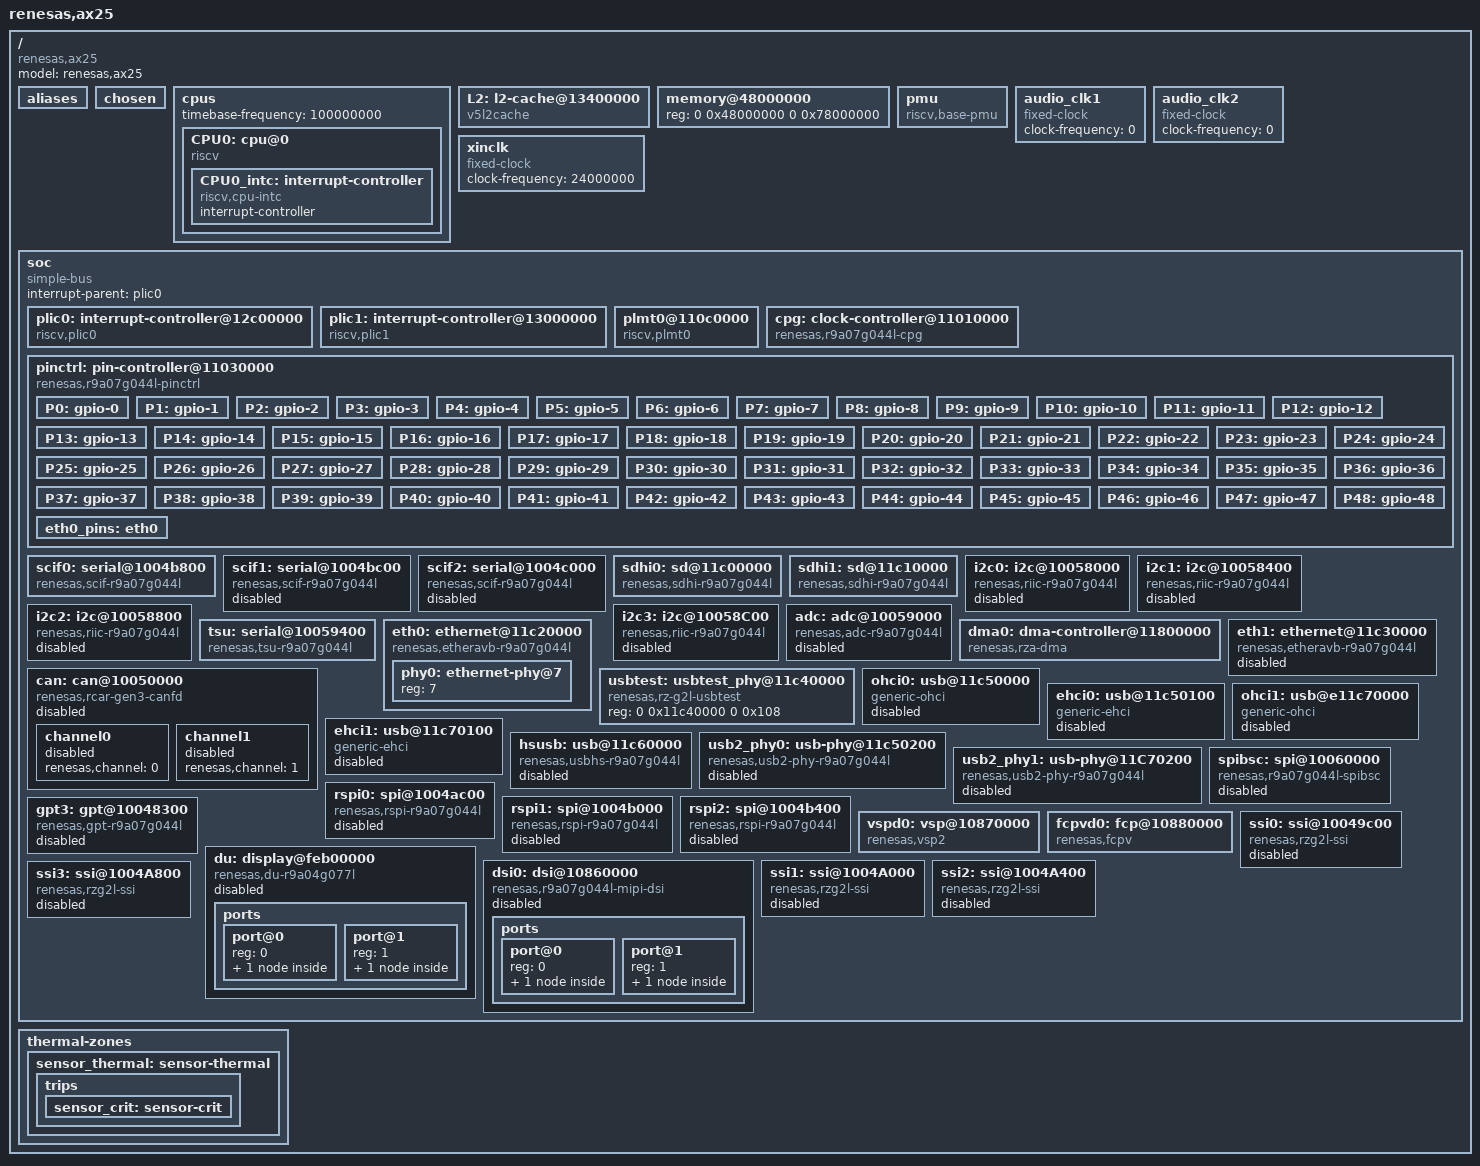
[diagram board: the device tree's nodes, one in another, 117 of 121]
// SPDX-License-Identifier: GPL-2.0
/*
 * Device Tree Source for the GR-Peach board
 *
 * Copyright (C) 2017 Jacopo Mondi <jacopo+renesas@jmondi.org>
 * Copyright (C) 2016 Renesas Electronics
 */

/dts-v1/;
#include <dt-bindings/gpio/gpio.h>
#include <dt-bindings/interrupt-controller/arm-gic.h>
#include <dt-bindings/clock/r9a07g044l-cpg.h>
#include <dt-bindings/pinctrl/rzg2l-pinctrl.h>

/ {
		#address-cells = <2>;
		#size-cells = <2>;
		compatible = "renesas,ax25";
		model = "renesas,ax25";

		aliases {
				serial0 = &scif0;
				i2c0 = &i2c0;
				i2c1 = &i2c1;
				i2c2 = &i2c2;
				i2c3 = &i2c3;
				spi0 = &rspi0;
				spi1 = &rspi1;
				spi2 = &rspi2;
		};

		chosen {
				bootargs = "console=ttyS0,115200n8	debug loglevel=7";
				stdout-path = "serial0:115200n8";
		};

		cpus {
				u-boot,dm-spl;
				#address-cells = <1>;
				#size-cells = <0>;
				timebase-frequency = <100000000>;
				CPU0: cpu@0 {
						u-boot,dm-spl;
						device_type = "cpu";
						reg = <0>;
						status = "okay";
						compatible = "riscv";
						riscv,isa = "rv64imafdc";
						riscv,priv-major = <1>;
						riscv,priv-minor = <10>;
						mmu-type = "riscv,sv39";
						clock-frequency = <100000000>;
						i-cache-size = <0x8000>;
						i-cache-line-size = <32>;
						d-cache-size = <0x8000>;
						d-cache-line-size = <32>;
						next-level-cache = <&L2>;
						CPU0_intc: interrupt-controller {
								u-boot,dm-spl;
								#interrupt-cells = <1>;
								interrupt-controller;
								compatible = "riscv,cpu-intc";
						};
				};
		};

		L2: l2-cache@13400000 {
				u-boot,dm-spl;
				compatible = "v5l2cache";
				cache-level = <2>;
				cache-size = <0x40000>;
				reg = <0x0 0x13400000 0x0 0x40000>;
				andes,inst-prefetch = <3>;
				andes,data-prefetch = <3>;
				/* The value format is <XRAMOCTL XRAMICTL> */
				andes,tag-ram-ctl = <0 0>;
				andes,data-ram-ctl = <0 0>;
		};

		memory@48000000 {
				u-boot,dm-spl;
				device_type = "memory";
				/* first 128MB is reserved for secure area. */
				reg = <0 0x48000000 0 0x78000000>;
		};

		pmu {
				compatible = "riscv,base-pmu";
		};


		/*
		 * The external audio clocks are configured as 0 Hz fixed frequency
		 * clocks by default.
		 * Boards that provide audio clocks should override them.
		 */
		audio_clk1: audio_clk1 {
				compatible = "fixed-clock";
				#clock-cells = <0>;
				clock-frequency = <0>;
		};

		audio_clk2: audio_clk2 {
				compatible = "fixed-clock";
				#clock-cells = <0>;
				clock-frequency = <0>;
		};

		xinclk: xinclk {
				compatible = "fixed-clock";
				#clock-cells = <0>;
				/* This value must be overridden by the board */
				clock-frequency = <0>;
		};

		soc: soc {
				u-boot,dm-spl;
				#address-cells = <2>;
				#size-cells = <2>;
				compatible = "simple-bus";
				interrupt-parent = <&plic0>;
				ranges;

				plic0: interrupt-controller@12c00000 {
						u-boot,dm-spl;
						compatible = "riscv,plic0";
						#address-cells = <2>;
						#interrupt-cells = <2>;
						interrupt-controller;
						reg = <0x0 0x12c00000 0x0 0x2000000>;
						riscv,ndev=<71>;
						interrupts-extended = <&CPU0_intc 11 &CPU0_intc 9>;
				};

				plic1: interrupt-controller@13000000 {
						u-boot,dm-spl;
						compatible = "riscv,plic1";
						#address-cells = <2>;
						#interrupt-cells = <2>;
						interrupt-controller;
						reg = <0x0 0x13000000 0x0 0x400000>;
						riscv,ndev=<2>;
						interrupts-extended = <&CPU0_intc 3>;
				};

				plmt0@110c0000 {
						u-boot,dm-spl;
						compatible = "riscv,plmt0";
						interrupts-extended = <&CPU0_intc 7>;
						reg = <0x0 0x110c0000 0x0 0x100000>;
				};

				cpg: clock-controller@11010000 {
						u-boot,dm-spl;
						compatible = "renesas,r9a07g044l-cpg";
						reg = <0 0x11010000 0 0x10000>;
						clocks = <&xinclk>;
						clock-names = "xinclk";
						#clock-cells = <2>;
						#reset-cells = <1>;
						#power-domain-cells = <0>;
				};

				pinctrl: pin-controller@11030000 {
						u-boot,dm-spl;
						compatible = "renesas,r9a07g044l-pinctrl";
						reg = <0 0x11030000 0 0x10000>;
						gpio-controller;
						#gpio-cells = <2>;
						gpio-ranges = <&pinctrl 0 0 392>;
						clocks = <&cpg CPG_MOD R9A07G044L_CLK_GPIO>;
				};

				scif0: serial@1004b800 {
						u-boot,dm-spl;
						compatible = "renesas,scif-r9a07g044l", "renesas,scif";
						reg = <0 0x1004b800 0 0x400>;
						interrupts = <380 4>, <382 4>, <383 4>, <381 4>, <384 4>, <384 4>;
						clocks = <&cpg CPG_MOD R9A07G044L_CLK_SCIF0>;
						clock-names = "fck";
						resets = <&cpg R9A07G044L_CLK_SCIF0>;
						power-domains = <&cpg>;
						status = "disable";
				};

				scif1: serial@1004bc00 {
						compatible = "renesas,scif-r9a07g044l", "renesas,scif";
						reg = <0 0x1004bc00 0 0x400>;
						interrupts = <385 4>, <387 4>, <388 4>, <386 4>, <389 4>, <389 4>;
						clocks = <&cpg CPG_MOD R9A07G044L_CLK_SCIF1>;
						clock-names = "fck";
						resets = <&cpg R9A07G044L_CLK_SCIF1>;
						power-domains = <&cpg>;
						status = "disable";
				};

				scif2: serial@1004c000 {
						compatible = "renesas,scif-r9a07g044l", "renesas,scif";
						reg = <0 0x1004c000 0 0x400>;
						interrupts = <390 4>, <392 4>, <393 4>, <391 4>, <394 4>, <394 4>;
						clocks = <&cpg CPG_MOD R9A07G044L_CLK_SCIF2>;
						clock-names = "fck";
						resets = <&cpg R9A07G044L_CLK_SCIF2>;
						power-domains = <&cpg>;
						status = "disable";
				};

				sdhi0: sd@11c00000 {
						compatible = "renesas,sdhi-r9a07g044l",
									 "renesas,rcar-gen3-sdhi";
						reg = <0 0x11c00000 0 0x10000>;
						interrupts = <104 4>, <105 4>;
						clocks = <&cpg CPG_MOD R9A07G044L_CLK_SDHI0>;
						resets = <&cpg R9A07G044L_CLK_SDHI0>;
						power-domains = <&cpg>;
						status = "disabled";
				};

				sdhi1: sd@11c10000 {
						compatible = "renesas,sdhi-r9a07g044l",
									 "renesas,rcar-gen3-sdhi";
						reg = <0x0 0x11c10000 0 0x10000>;
						interrupts = <106 4>, <107 4>;
						clocks = <&cpg CPG_MOD R9A07G044L_CLK_SDHI1>;
						resets = <&cpg R9A07G044L_CLK_SDHI1>;
						power-domains = <&cpg>;
						status = "disabled";
				};

				i2c0: i2c@10058000 {
						#address-cells = <1>;
						#size-cells = <0>;
						compatible = "renesas,riic-r9a07g044l",
										"renesas,riic-rz";
						reg = <0 0x10058000 0 0x44>;
						interrupts = <350  4>, <348 4>, <349 4>, <352 4>, <353 4>, <351 4>, <354 4>, <355 4>;
						clocks = <&cpg CPG_MOD R9A07G044L_CLK_I2C0>;
						clock-frequency = <100000>;
						resets = <&cpg R9A07G044L_CLK_I2C0>;
						status = "disabled";
				};

				i2c1: i2c@10058400 {
						#address-cells = <1>;
						#size-cells = <0>;
						compatible = "renesas,riic-r9a07g044l",
										"renesas,riic-rz";
						reg = <0 0x10058400 0 0x44>;
						interrupts = <358  4>, <356 4>, <357 4>, <360 4>, <361 4>, <359 4>, <362 4>, <363 4>;
						clocks = <&cpg CPG_MOD R9A07G044L_CLK_I2C1>;
						clock-frequency = <100000>;
						resets = <&cpg R9A07G044L_CLK_I2C1>;
						status = "disabled";
				};

				i2c2: i2c@10058800 {
						#address-cells = <1>;
						#size-cells = <0>;
						compatible = "renesas,riic-r9a07g044l",
										"renesas,riic-rz";
						reg = <0 0x10058800 0 0x44>;
						interrupts = <366  4>, <364 4>, <365 4>, <368 4>, <369 4>, <367 4>, <370 4>, <371 4>;
						clocks = <&cpg CPG_MOD R9A07G044L_CLK_I2C2>;
						clock-frequency = <100000>;
						resets = <&cpg R9A07G044L_CLK_I2C2>;
						status = "disabled";
				};

				i2c3: i2c@10058C00 {
						#address-cells = <1>;
						#size-cells = <0>;
						compatible = "renesas,riic-r9a07g044l",
										"renesas,riic-rz";
						reg = <0 0x10058c00 0 0x44>;
						interrupts = <374  4>, <372 4>, <373 4>, <376 4>, <377 4>, <375 4>, <378 4>, <379 4>;
						clocks = <&cpg CPG_MOD R9A07G044L_CLK_I2C3>;
						clock-frequency = <100000>;
						resets = <&cpg R9A07G044L_CLK_I2C3>;
						status = "disabled";
				};

				adc: adc@10059000 {
						compatible = "renesas,adc-r9a07g044l";
						reg = <0 0x10059000 0 0x400>;
						interrupts = <347  4>;
						clocks = <&cpg CPG_MOD R9A07G044L_CLK_ADC>;
						resets = <&cpg R9A07G044L_CLK_ADC>;
						power-domains = <&cpg>;
						status = "disabled";
				};

				tsu: serial@10059400 {
						compatible = "renesas,tsu-r9a07g044l";
						reg = <0 0x10059400 0 0x400>;
						clocks = <&cpg CPG_MOD R9A07G044L_CLK_TSU_PCLK>;
						resets = <&cpg R9A07G044L_CLK_TSU_PCLK>;
						clock-names = "tsu";
						thermal-cal = <1>;
						#thermal-sensor-cells = <0>;
						power-domains = <&cpg>;
				};

				dma0: dma-controller@11800000 {
						compatible = "renesas,rza-dma";
						reg =	<0 0x11820000 0 0x10000>,
								<0 0x11830000 0 0x10000>;

						interrupts =	<125 4>, <126 4>, <127 4>, <128 4>,
								<129 4>, <130 4>, <131 4>, <132 4>,
								<133 4>, <134 4>, <135 4>, <136 4>,
								<137 4>, <138 4>, <139 4>, <140 4>,
								<141 4>;
						interrupt-names = "ch0", "ch1", "ch2", "ch3",
								"ch4", "ch5", "ch6", "ch7",
								"ch8", "ch9", "ch10", "ch11",
								"ch12", "ch13", "ch14", "ch15",
								"error";
						dma-channels = <16>;
						#dma-cells = <1>;
						clocks = <&cpg CPG_MOD R9A07G044L_CLK_DMAC>;
						resets = <&cpg R9A07G044L_CLK_DMAC>;
				};

				can: can@10050000 {
						compatible = "renesas,rcar-gen3-canfd",
										"renesas,r9a07g044l-canfd";
						reg = <0 0x10050000 0 0x6000>;
						interrupts =	<426 4>, <422 4>, <428 4>, <423 4>, <429 4>, <424 4>, <425 4>, <427 4>;
						clocks = <&cpg CPG_MOD R9A07G044L_CLK_CANFD>,
								 <&cpg CPG_CORE R9A07G044L_CLK_P0>;
						clock-names = "fck","canfd";
						resets = <&cpg R9A07G044L_CLK_CANFD>;
						power-dmains = <&cpg>;
						status = "disabled";
						channel0 {
								renesas,channel = <0>;
								status = "disabled";
						};
						channel1 {
								renesas,channel = <1>;
								status = "disabled";
						};
				};

				eth0: ethernet@11c20000 {
						compatible = "renesas,etheravb-r9a07g044l";
						reg = <0 0x11c20000 0 0x10000>;
						interrupts = <84 4>, <85 4>, <86 4>;
						clocks = <&cpg CPG_MOD R9A07G044L_CLK_ETH0>;
						resets = <&cpg R9A07G044L_CLK_ETH0>;
						power-domains = <&cpg>;
						phy-mode = "rgmii";
						#address-cells = <1>;
						#size-cells = <0>;
						eth-pin-mode-switch = <&pinctrl 0>;
						status = "disabled";
				};

				eth1: ethernet@11c30000 {
						compatible = "renesas,etheravb-r9a07g044l";
						reg = <0 0x11c30000 0 0x10000>;
						interrupts = <87 4>, <88 4>, <89 4>;
						clocks = <&cpg CPG_MOD R9A07G044L_CLK_ETH1>;
						resets = <&cpg R9A07G044L_CLK_ETH1>;
						power-domains = <&cpg>;
						phy-mode = "rgmii";
						#address-cells = <1>;
						#size-cells = <0>;
						eth-pin-mode-switch = <&pinctrl 1>;
						status = "disabled";
				};

				usbtest: usbtest_phy@11c40000 {
						compatible = "renesas,rz-g2l-usbtest";
						reg = <0 0x11c40000 0 0x108>;
						#phy-cells = <0>;
				};

				ohci0: usb@11c50000 {
						compatible = "generic-ohci";
						reg = <0 0x11c50000 0 0x100>;
						interrupts = <91 4>;
						clocks = <&cpg CPG_MOD R9A07G044L_CLK_USB0>;
						resets = <&cpg R9A07G044L_CLK_USB0>;
						phys = <&usbtest>, <&usb2_phy0>;
						phy-names = "usb";
						power-domains = <&cpg>;
						status = "disabled";
				};

				ehci0: usb@11c50100 {
						compatible = "generic-ehci";
						reg = <0 0x11c50100 0 0x100>;
						interrupts = <92 4>;
						clocks = <&cpg CPG_MOD R9A07G044L_CLK_USB0>;
						resets = <&cpg R9A07G044L_CLK_USB0>;
						phys = <&usbtest>, <&usb2_phy0>;
						phy-names = "usb";
						power-domains = <&cpg>;
						status = "disabled";
				};

				ohci1: usb@e11c70000 {
						compatible = "generic-ohci";
						reg = <0 0x11c70000 0 0x100>;
						interrupts = <96 4>;
						clocks = <&cpg CPG_MOD R9A07G044L_CLK_USB1>;
						resets = <&cpg R9A07G044L_CLK_USB1>;
						phys = <&usbtest>, <&usb2_phy1>;
						phy-names = "usb";
						power-domains = <&cpg>;
						status = "disabled";
				};

				ehci1: usb@11c70100 {
						compatible = "generic-ehci";
						reg = <0 0x11c70100 0 0x100>;
						interrupts = <97 4>;
						clocks = <&cpg CPG_MOD R9A07G044L_CLK_USB1>;
						resets = <&cpg R9A07G044L_CLK_USB1>;
						phys = <&usbtest>, <&usb2_phy1>;
						phy-names = "usb";
						power-domains = <&cpg>;
						status = "disabled";
				};

				hsusb: usb@11c60000 {
						compatible = "renesas,usbhs-r9a07g044l",
									 "renesas,g2l-usbhs";
						reg = <0 0x11c60000 0 0x724>;
						interrupts = <100 4>;
						clocks = <&cpg CPG_MOD R9A07G044L_CLK_USB0>;
						resets = <&cpg R9A07G044L_CLK_USB0>;
						renesas,buswait = <7>;
						phys = <&usbtest>, <&usb2_phy0>;
						phy-names = "usb";
						power-domains = <&cpg>;
						status = "disabled";
				};

				usb2_phy0: usb-phy@11c50200 {
						compatible = "renesas,usb2-phy-r9a07g044l",
									 "renesas,rcar-gen3-usb2-phy";
						reg = <0 0x11c50200 0 0x700>;
						interrupts = <90 4>;
						clocks = <&cpg CPG_MOD R9A07G044L_CLK_USB0>;
						power-domains = <&cpg>;
						resets = <&cpg R9A07G044L_CLK_USB0>;
						#phy-cells = <0>;
						status = "disabled";
				};

				usb2_phy1: usb-phy@11C70200 {
						compatible = "renesas,usb2-phy-r9a07g044l",
									 "renesas,rcar-gen3-usb2-phy";
						reg = <0 0x11C70200 0 0x700>;
						interrupts = <95 4>;
						clocks = <&cpg CPG_MOD R9A07G044L_CLK_USB1>;
						power-domains = <&cpg>;
						resets = <&cpg R9A07G044L_CLK_USB1>;
						#phy-cells = <0>;
						status = "disabled";
				};

				spibsc: spi@10060000 {
						compatible = "renesas,r9a07g044l-spibsc";
						reg = <0 0x10060000 0 0x78>, <0 0x20000000 0 0x10000000>;
						interrupts = <41 4>;
						clocks = <&cpg CPG_MOD R9A07G044L_CLK_SPI>;
						resets = <&cpg R9A07G044L_CLK_SPI>;
						power-domains = <&cpg>;
						#address-cells = <1>;
						#size-cells = <0>;
						status = "disabled";
				};

				rspi0: spi@1004ac00 {
						#address-cells = <1>;
						#size-cells = <0>;
						compatible = "renesas,rspi-r9a07g044l", "renesas,rspi-rz";
						reg = <0 0x1004ac00 0 0x24>;
						interrupts = <415 4>, <413 4>, <414 4>;
						interrupt-names = "error", "rx", "tx";
						clocks = <&cpg CPG_MOD R9A07G044L_CLK_RSPI0>;
						resets = <&cpg R9A07G044L_CLK_RSPI0>;
						power-domains = <&cpg>;
						num-cs = <1>;
						status = "disabled";
				};

				rspi1: spi@1004b000 {
						#address-cells = <1>;
						#size-cells = <0>;
						compatible = "renesas,rspi-r9a07g044l", "renesas,rspi-rz";
						reg = <0 0x1004b000 0 0x24>;
						interrupts = <418 4>, <416 4>, <417 4>;
						interrupt-names = "error", "rx", "tx";
						clocks = <&cpg CPG_MOD R9A07G044L_CLK_RSPI1>;
						resets = <&cpg R9A07G044L_CLK_RSPI1>;
						power-domains = <&cpg>;
						num-cs = <1>;
						status = "disabled";
				};

				rspi2: spi@1004b400 {
						#address-cells = <1>;
						#size-cells = <0>;
						compatible = "renesas,rspi-r9a07g044l", "renesas,rspi-rz";
						reg = <0 0x1004b400 0 0x24>;
						interrupts = <421 4>, <419 4>, <420 4>;
						interrupt-names = "error", "rx", "tx";
						clocks = <&cpg CPG_MOD R9A07G044L_CLK_RSPI2>;
						resets = <&cpg R9A07G044L_CLK_RSPI2>;
						power-domains = <&cpg>;
						num-cs = <1>;
						status = "disabled";
				};

				gpt3: gpt@10048300 {
						compatible = "renesas,gpt-r9a07g044l";
						reg = <0 0x10048300 0 0xa4>;
						#pwm-cells = <2>;
						interrupts = <257 4>, <258 4>, <259 4>, <260 4>,
								<261 4>, <262 4>, <263 4>, <264 4>,
								<265 4>, <266 4>, <267 4>, <268 4>,
								<269 4>;
						interrupt-names = "gtcia", "gtcib", "gtcic", "gtcid",
								"gtcie", "gtcif", "gtciada", "gtciadb",
								"gtciv", "gtciu", "gtcih", "gtcil",
								"gtdei";
						clocks = <&cpg CPG_MOD R9A07G044L_CLK_GPT>;
						resets =  <&cpg R9A07G044L_CLK_GPT>;
						status = "disabled";
				};

				vspd0: vsp@10870000 {
						compatible = "renesas,vsp2";
						reg = <0 0x10870000 0 0x10000>;
						interrupts = <149 4>;
						clocks = <&cpg CPG_MOD R9A07G044L_CLK_LCDC>;
						resets = <&cpg R9A07G044L_CLK_LCDC>;
						power-domains = <&cpg>;
						renesas,fcp = <&fcpvd0>;
				};

				fcpvd0: fcp@10880000 {
						compatible = "renesas,fcpv";
						reg = <0 0x10880000 0 0x10000>;
						clocks = <&cpg CPG_MOD R9A07G044L_CLK_LCDC>;
						resets = <&cpg R9A07G044L_CLK_LCDC>;
						power-domains = <&cpg>;
				};

				du: display@feb00000 {
						compatible = "renesas,du-r9a04g077l";
						reg = <0 0x10890000 0 0x10000>;
						interrupts = <152 4>;
						clocks = <&cpg CPG_MOD R9A07G044L_CLK_LCDC>;
						clock-names = "du.0";
						resets = <&cpg R9A07G044L_CLK_LCDC>;
						reset-names = "du.0";
						vsps = <&vspd0 0>;
						power-domains = <&cpg>;
						status = "disabled";

						ports {
								#address-cells = <1>;
								#size-cells = <0>;

								port@0 {
										reg = <0>;
										du_out_rgb: endpoint {
										};
								};

								port@1 {
										reg = <1>;
										du_out_dsi0: endpoint {
												remote-endpoint = <&dsi0_in>;
										};
								};
						};
				};

				dsi0: dsi@10860000 {
						compatible = "renesas,r9a07g044l-mipi-dsi";
						reg =	<0 0x10860000 0 0x10000>, /* LINK */
								<0 0x10850000 0 0x10000>; /* DPHY */

						clocks = <&cpg CPG_MOD R9A07G044L_CLK_MIPI_DSI>;
						resets = <&cpg R9A07G044L_CLK_MIPI_DSI>;
						power-domains = <&cpg>;
						status = "disabled";

						ports {
								#address-cells = <1>;
								#size-cells = <0>;

								port@0 {
										reg = <0>;
										dsi0_in: endpoint {
										remote-endpoint = <&du_out_dsi0>;
										};
								};

								port@1 {
										reg = <1>;
										dsi0_out: endpoint {
										};
								};
						};
				};

				ssi0: ssi@10049c00 {
						#sound-dai-cells = <0>;
						compatible = "renesas,rzg2l-ssi";
						reg = <0 0x10049c00 0 0x00000028>;
						interrupts = <326 4>, <327 4>, <328 4>;
						interrupt-names = "int", "rx", "tx";
						clocks = <&cpg CPG_MOD R9A07G044L_CLK_SSI0> ,
								 <&audio_clk1>,
								 <&audio_clk2>;
						clock-names = "ssi", "audio_clk1", "audio_clk2";
						resets = <&cpg R9A07G044L_CLK_SSI0>;
						power-domains = <&cpg>;
						status = "disabled";
				};

				ssi1: ssi@1004A000 {
						#sound-dai-cells = <0>;
						compatible = "renesas,rzg2l-ssi";
						reg = <0 0x1004A000 0 0x00000028>;
						interrupts = <330 4>, <331 4>, <332 4>;
						interrupt-names = "int", "rx", "tx";
						clocks = <&cpg CPG_MOD R9A07G044L_CLK_SSI1>,
								 <&audio_clk1>,
								 <&audio_clk2>;
						clock-names = "ssi", "audio_clk1", "audio_clk2";
						resets = <&cpg R9A07G044L_CLK_SSI1>;
						power-domains = <&cpg>;
						status = "disabled";
				};

				ssi2: ssi@1004A400 {
						#sound-dai-cells = <0>;
						compatible = "renesas,rzg2l-ssi";
						reg = <0 0x1004A400 0 0x00000028>;
						interrupts = <334 4>, <335 4>, <336 4>;
						interrupt-names = "int", "rx", "tx";
						clocks = <&cpg CPG_MOD R9A07G044L_CLK_SSI2>,
								 <&audio_clk1>,
								 <&audio_clk2>;
						clock-names = "ssi", "audio_clk1", "audio_clk2";
						resets = <&cpg R9A07G044L_CLK_SSI2>;
						power-domains = <&cpg>;
						status = "disabled";
				};

				ssi3: ssi@1004A800 {
						#sound-dai-cells = <0>;
						compatible = "renesas,rzg2l-ssi";
						reg = <0 0x1004A800 0 0x00000028>;
						interrupts = <338 4>, <339 4>, <340 4>;
						interrupt-names = "int", "rx", "tx";
						clocks = <&cpg CPG_MOD R9A07G044L_CLK_SSI3>,
								 <&audio_clk1>,
								 <&audio_clk2>;
						clock-names = "ssi", "audio_clk1", "audio_clk2";
						resets = <&cpg R9A07G044L_CLK_SSI3>;
						power-domains = <&cpg>;
						status = "disabled";
				};
		};

		thermal-zones {
				sensor_thermal: sensor-thermal {
						polling-delay-passive = <250>;
						polling-delay = <1000>;
						sustainable-power = <3874>;
						thermal-sensors = <&tsu 0>;

						trips {
								sensor_crit: sensor-crit {
								temperature = <110000>;
								hysteresis = <1000>;
								type = "critical";
								};
						};
				};
		};

};


&pinctrl {
	P0: gpio-0 {
		gpio-controller;
		#gpio-cells = <2>;
		gpio-ranges = <&pinctrl 0 0 2>;
	};

	P1: gpio-1 {
		gpio-controller;
		#gpio-cells = <2>;
		gpio-ranges = <&pinctrl 0 8 2>;
	};

	P2: gpio-2 {
		gpio-controller;
		#gpio-cells = <2>;
		gpio-ranges = <&pinctrl 0 16 2>;
	};

	P3: gpio-3 {
		gpio-controller;
		#gpio-cells = <2>;
		gpio-ranges = <&pinctrl 0 24 2>;
	};

	P4: gpio-4 {
		gpio-controller;
		#gpio-cells = <2>;
		gpio-ranges = <&pinctrl 0 32 2>;
	};

	P5: gpio-5 {
		gpio-controller;
		#gpio-cells = <2>;
		gpio-ranges = <&pinctrl 0 40 3>;
	};

	P6: gpio-6 {
		gpio-controller;
		#gpio-cells = <2>;
		gpio-ranges = <&pinctrl 0 48 2>;
	};

	P7: gpio-7 {
		gpio-controller;
		#gpio-cells = <2>;
		gpio-ranges = <&pinctrl 0 56 3>;
	};

	P8: gpio-8 {
		gpio-controller;
		#gpio-cells = <2>;
		gpio-ranges = <&pinctrl 0 64 3>;
	};

	P9: gpio-9 {
		gpio-controller;
		#gpio-cells = <2>;
		gpio-ranges = <&pinctrl 0 72 2>;
	};

	P10: gpio-10 {
		gpio-controller;
		#gpio-cells = <2>;
		gpio-ranges = <&pinctrl 0 80 2>;
	};

	P11: gpio-11 {
		gpio-controller;
		#gpio-cells = <2>;
		gpio-ranges = <&pinctrl 0 88 2>;
	};

	P12: gpio-12 {
		gpio-controller;
		#gpio-cells = <2>;
		gpio-ranges = <&pinctrl 0 96 2>;
	};

	P13: gpio-13 {
		gpio-controller;
		#gpio-cells = <2>;
		gpio-ranges = <&pinctrl 0 104 3>;
	};

	P14: gpio-14 {
		gpio-controller;
		#gpio-cells = <2>;
		gpio-ranges = <&pinctrl 0 112 2>;
	};

	P15: gpio-15 {
		gpio-controller;
		#gpio-cells = <2>;
		gpio-ranges = <&pinctrl 0 120 2>;
	};

	P16: gpio-16 {
		gpio-controller;
		#gpio-cells = <2>;
		gpio-ranges = <&pinctrl 0 128 2>;
	};

	P17: gpio-17 {
		gpio-controller;
		#gpio-cells = <2>;
		gpio-ranges = <&pinctrl 0 136 3>;
	};

	P18: gpio-18 {
		gpio-controller;
		#gpio-cells = <2>;
		gpio-ranges = <&pinctrl 0 144 2>;
	};

	P19: gpio-19 {
		gpio-controller;
		#gpio-cells = <2>;
		gpio-ranges = <&pinctrl 0 152 2>;
	};

	P20: gpio-20 {
		gpio-controller;
		#gpio-cells = <2>;
		gpio-ranges = <&pinctrl 0 160 3>;
	};

	P21: gpio-21 {
		gpio-controller;
		#gpio-cells = <2>;
		gpio-ranges = <&pinctrl 0 168 2>;
	};

	P22: gpio-22 {
		gpio-controller;
		#gpio-cells = <2>;
		gpio-ranges = <&pinctrl 0 176 2>;
	};

	P23: gpio-23 {
		gpio-controller;
		#gpio-cells = <2>;
		gpio-ranges = <&pinctrl 0 184 2>;
	};

	P24: gpio-24 {
		gpio-controller;
		#gpio-cells = <2>;
		gpio-ranges = <&pinctrl 0 192 2>;
	};

	P25: gpio-25 {
		gpio-controller;
		#gpio-cells = <2>;
		gpio-ranges = <&pinctrl 0 200 2>;
	};

	P26: gpio-26 {
		gpio-controller;
		#gpio-cells = <2>;
		gpio-ranges = <&pinctrl 0 208 2>;
	};

	P27: gpio-27 {
		gpio-controller;
		#gpio-cells = <2>;
		gpio-ranges = <&pinctrl 0 216 2>;
	};

	P28: gpio-28 {
		gpio-controller;
		#gpio-cells = <2>;
		gpio-ranges = <&pinctrl 0 224 2>;
	};

	P29: gpio-29 {
		gpio-controller;
		#gpio-cells = <2>;
		gpio-ranges = <&pinctrl 0 232 2>;
	};

	P30: gpio-30 {
		gpio-controller;
		#gpio-cells = <2>;
		gpio-ranges = <&pinctrl 0 240 2>;
	};

	P31: gpio-31 {
		gpio-controller;
		#gpio-cells = <2>;
		gpio-ranges = <&pinctrl 0 248 2>;
	};

	P32: gpio-32 {
		gpio-controller;
		#gpio-cells = <2>;
		gpio-ranges = <&pinctrl 0 256 2>;
	};

	P33: gpio-33 {
		gpio-controller;
		#gpio-cells = <2>;
		gpio-ranges = <&pinctrl 0 264 2>;
	};

	P34: gpio-34 {
		gpio-controller;
		#gpio-cells = <2>;
		gpio-ranges = <&pinctrl 0 272 2>;
	};

	P35: gpio-35 {
		gpio-controller;
		#gpio-cells = <2>;
		gpio-ranges = <&pinctrl 0 280 2>;
	};

	P36: gpio-36 {
		gpio-controller;
		#gpio-cells = <2>;
		gpio-ranges = <&pinctrl 0 288 2>;
	};

	P37: gpio-37 {
		gpio-controller;
		#gpio-cells = <2>;
		gpio-ranges = <&pinctrl 0 296 3>;
	};

	P38: gpio-38 {
		gpio-controller;
		#gpio-cells = <2>;
		gpio-ranges = <&pinctrl 0 304 2>;
	};

	P39: gpio-39 {
		gpio-controller;
		#gpio-cells = <2>;
		gpio-ranges = <&pinctrl 0 312 3>;
	};

	P40: gpio-40 {
		gpio-controller;
		#gpio-cells = <2>;
		gpio-ranges = <&pinctrl 0 320 3>;
	};

	P41: gpio-41 {
		gpio-controller;
		#gpio-cells = <2>;
		gpio-ranges = <&pinctrl 0 328 2>;
	};

	P42: gpio-42 {
		gpio-controller;
		#gpio-cells = <2>;
		gpio-ranges = <&pinctrl 0 336 5>;
	};

	P43: gpio-43 {
		gpio-controller;
		#gpio-cells = <2>;
		gpio-ranges = <&pinctrl 0 344 4>;
	};

	P44: gpio-44 {
		gpio-controller;
		#gpio-cells = <2>;
		gpio-ranges = <&pinctrl 0 352 4>;
	};

	P45: gpio-45 {
		gpio-controller;
		#gpio-cells = <2>;
		gpio-ranges = <&pinctrl 0 360 4>;
	};

	P46: gpio-46 {
		gpio-controller;
		#gpio-cells = <2>;
		gpio-ranges = <&pinctrl 0 368 4>;
	};

	P47: gpio-47 {
		gpio-controller;
		#gpio-cells = <2>;
		gpio-ranges = <&pinctrl 0 376 4>;
	};

	P48: gpio-48 {
		gpio-controller;
		#gpio-cells = <2>;
		gpio-ranges = <&pinctrl 0 384 5>;
	};
};


&pinctrl {
	eth0_pins: eth0 {
		pinmux = <RZG2L_PINMUX(20, 0, 1)>,
				<RZG2L_PINMUX(20, 1, 1)>,
				<RZG2L_PINMUX(20, 2, 1)>,
				<RZG2L_PINMUX(21, 0, 1)>,
				<RZG2L_PINMUX(21, 1, 1)>,
				<RZG2L_PINMUX(22, 0, 1)>,
				<RZG2L_PINMUX(22, 1, 1)>,
				<RZG2L_PINMUX(23, 0, 1)>,
				<RZG2L_PINMUX(23, 1, 1)>,
				<RZG2L_PINMUX(24, 0, 1)>,
				<RZG2L_PINMUX(24, 1, 1)>,
				<RZG2L_PINMUX(25, 0, 1)>,
				<RZG2L_PINMUX(25, 1, 1)>,
				<RZG2L_PINMUX(26, 0, 1)>,
				<RZG2L_PINMUX(26, 1, 1)>,
				<RZG2L_PINMUX(27, 0, 1)>,
				<RZG2L_PINMUX(27, 1, 1)>,
				<RZG2L_PINMUX(28, 0, 1)>,
				<RZG2L_PINMUX(28, 1, 1)>;
	};
};

&xinclk {
        clock-frequency = <24000000>;
};

&scif0 {
	status = "okay";
	clock = <100000000>;
};

&sdhi0 {
	/* pinctrl placeholder
	 * If this channel is used for interfacing with a SD card, a power enable
	 * pin (SD0_PWR_EN) must be defined.
	 * The SD0_PWR_EN pin is associated with P4_1.
	 * A HIGH signal on SD0_PWR_EN will enable supply voltage for SD card.
	*/
	bus-width = <8>;
	status = "okay";
};

&sdhi1 {
	/* pinctrl placeholder
	 * A power enable pin (SD1_PWR_EN) must be defined to interface with a
	 * SD card.
	 * The SD1_PWR_EN pin is associated with P39_2.
	 * A HIGH signal on SD1_PWR_EN will enable supply voltage for SD card.
	*/
	bus-width = <4>;
	status = "okay";
};

&eth0 {
	pinctrl-names = "default";
	pinctrl-0 = <&eth0_pins>;
	phy-handle = <&phy0>;
	phy-mode = "rgmii";
	status = "okay";

	phy0: ethernet-phy@7 {
		reg = <7>;
	};
};

